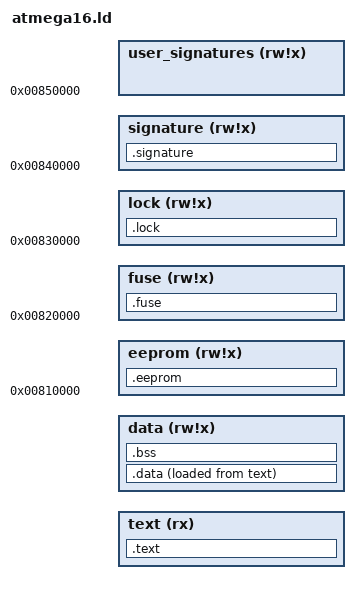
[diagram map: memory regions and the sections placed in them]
OUTPUT_FORMAT("elf32-avr","elf32-avr","elf32-avr")
OUTPUT_ARCH(avr:5)

__TEXT_REGION_ORIGIN__ = DEFINED(__TEXT_REGION_ORIGIN__) ? __TEXT_REGION_ORIGIN__ : 0;
__DATA_REGION_ORIGIN__ = DEFINED(__DATA_REGION_ORIGIN__) ? __DATA_REGION_ORIGIN__ : 0x800060;
__TEXT_REGION_LENGTH__ = DEFINED(__TEXT_REGION_LENGTH__) ? __TEXT_REGION_LENGTH__ : 128K;
__DATA_REGION_LENGTH__ = DEFINED(__DATA_REGION_LENGTH__) ? __DATA_REGION_LENGTH__ : 0xffa0;
__EEPROM_REGION_LENGTH__ = DEFINED(__EEPROM_REGION_LENGTH__) ? __EEPROM_REGION_LENGTH__ : 64K;
__FUSE_REGION_LENGTH__ = DEFINED(__FUSE_REGION_LENGTH__) ? __FUSE_REGION_LENGTH__ : 1K;
__LOCK_REGION_LENGTH__ = DEFINED(__LOCK_REGION_LENGTH__) ? __LOCK_REGION_LENGTH__ : 1K;
__SIGNATURE_REGION_LENGTH__ = DEFINED(__SIGNATURE_REGION_LENGTH__) ? __SIGNATURE_REGION_LENGTH__ : 1K;
__USER_SIGNATURE_REGION_LENGTH__ = DEFINED(__USER_SIGNATURE_REGION_LENGTH__) ? __USER_SIGNATURE_REGION_LENGTH__ : 1K;

MEMORY
{
  text   			(rx)   : ORIGIN = __TEXT_REGION_ORIGIN__, LENGTH = __TEXT_REGION_LENGTH__
  data   			(rw!x) : ORIGIN = __DATA_REGION_ORIGIN__, LENGTH = __DATA_REGION_LENGTH__
  eeprom 			(rw!x) : ORIGIN = 0x810000, LENGTH = __EEPROM_REGION_LENGTH__
  fuse      		(rw!x) : ORIGIN = 0x820000, LENGTH = __FUSE_REGION_LENGTH__
  lock      		(rw!x) : ORIGIN = 0x830000, LENGTH = __LOCK_REGION_LENGTH__
  signature 		(rw!x) : ORIGIN = 0x840000, LENGTH = __SIGNATURE_REGION_LENGTH__
  user_signatures 	(rw!x) : ORIGIN = 0x850000, LENGTH = __USER_SIGNATURE_REGION_LENGTH__
}

SECTIONS
{
  /* Internal text space or external memory.  */
  .text:
  {
	*(.isr_vector)
    KEEP(*(.isr_vector))
	
    *(.text)
    . = ALIGN(2);
     *(.text.*)
    . = ALIGN(2);
  }  > text
  
  _la_data = LOADADDR(.data);
  .data:
  {
    _sdata = .;
    *(.data)
     *(.data*)
     _edata = .;
  }  > data AT> text
  .bss  ADDR(.data) + SIZEOF (.data)   : AT (ADDR (.bss))
  {
    _sbss = .;
    *(.bss)
     *(.bss*)
    *(COMMON)
    _ebss = .;
  }  > data
  
  .eeprom  :
  {
    /* See .data above...  */
    KEEP(*(.eeprom*))
     __eeprom_end = . ;
  }  > eeprom
  .fuse  :
  {
    KEEP(*(.fuse))
    KEEP(*(.lfuse))
    KEEP(*(.hfuse))
    KEEP(*(.efuse))
  }  > fuse
  .lock  :
  {
    KEEP(*(.lock*))
  }  > lock
  .signature  :
  {
    KEEP(*(.signature*))
  }  > signature
}
